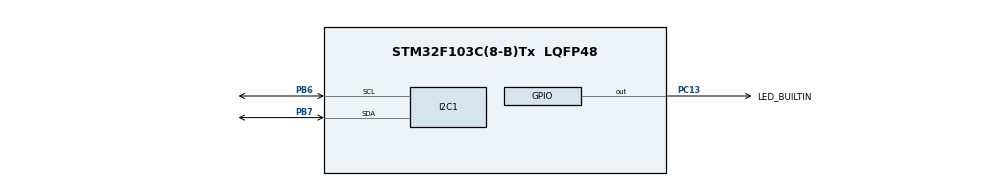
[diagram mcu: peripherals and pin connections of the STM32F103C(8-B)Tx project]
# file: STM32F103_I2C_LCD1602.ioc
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Mcu.Family=STM32F1
Mcu.Name=STM32F103C(8-B)Tx
Mcu.Package=LQFP48
NVIC.I2C1_EV_IRQn=true\:1\:0\:true\:false\:true\:true\:true\:true
NVIC.PriorityGroup=NVIC_PRIORITYGROUP_4
NVIC.RTC_IRQn=true\:0\:0\:false\:false\:true\:true\:true\:true
PA13.Mode=Serial_Wire
PA13.Signal=SYS_JTMS-SWDIO
PA14.Mode=Serial_Wire
PA14.Signal=SYS_JTCK-SWCLK
PB6.Mode=I2C
PB6.Signal=I2C1_SCL
PB7.Mode=I2C
PB7.Signal=I2C1_SDA
PC13-TAMPER-RTC.GPIO_Label=LED_BUILTIN
PC13-TAMPER-RTC.Signal=GPIO_Output
PC14-OSC32_IN.Mode=LSE-External-Oscillator
PC14-OSC32_IN.Signal=RCC_OSC32_IN
PC15-OSC32_OUT.Mode=LSE-External-Oscillator
PC15-OSC32_OUT.Signal=RCC_OSC32_OUT
ProjectManager.HeapSize=0x200
ProjectManager.StackSize=0x400
ProjectManager.TargetToolchain=Makefile
RCC.APB1Freq_Value=8000000
RCC.APB2Freq_Value=8000000
RCC.RTCClockSelection=RCC_RTCCLKSOURCE_LSE
RTC.Date=11
RTC.Format=RTC_FORMAT_BIN
RTC.Month=RTC_MONTH_NOVEMBER
RTC.Year=24
VP_RTC_VS_RTC_Activate.Mode=RTC_Enabled
VP_RTC_VS_RTC_Calendar.Mode=RTC_Calendar
board=custom

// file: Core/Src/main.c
/* USER CODE BEGIN Header */
/**
 ******************************************************************************
 * @file           : main.c
 * @brief          : Main program body
 ******************************************************************************
 * @attention
 *
 * Copyright (c) 2024 STMicroelectronics.
 * All rights reserved.
 *
 * This software is licensed under terms that can be found in the LICENSE file
 * in the root directory of this software component.
 * If no LICENSE file comes with this software, it is provided AS-IS.
 *
 ******************************************************************************
 */
/* USER CODE END Header */
#include "main.h"

/* USER CODE BEGIN Includes */
#include <stdio.h>

#include "hd44780.h"
/* USER CODE END Includes */

I2C_HandleTypeDef hi2c1;

RTC_HandleTypeDef hrtc;

/* USER CODE BEGIN PV */
Hd44780_Handle_t lcd_handle;
I2cConfig_t lcdi2c_config;

/* USER CODE END PV */

void SystemClock_Config(void);
static void MX_GPIO_Init(void);
static void MX_I2C1_Init(void);
static void MX_RTC_Init(void);
/* USER CODE BEGIN PFP */
void ToggleLED(void);

/* USER CODE END PFP */

int main(void)
{

  /* MCU Configuration--------------------------------------------------------*/

  /* Reset of all peripherals, Initializes the Flash interface and the Systick. */
  HAL_Init();

  /* Configure the system clock */
  SystemClock_Config();

  /* Initialize all configured peripherals */
  MX_GPIO_Init();
  MX_I2C1_Init();
  MX_RTC_Init();
  /* USER CODE BEGIN 2 */

    // initialize LCD
    lcdi2c_config.hi2c = &hi2c1;
    lcdi2c_config.lcd_addr = LCD_HAL_I2C_ADDRESS_DEFAULT;

    lcd_handle.i2cConfig = &lcdi2c_config;
    lcd_handle.init.cols = 16u;
    lcd_handle.init.rows = 2u;
    lcd_handle.init.num_dispLines = HD44780_FS_NDL_2_LINE;
    lcd_handle.init.char_font = HD44780_FS_FONT_5X8_DOTS;

    lcd_handle._status._ledState = 0u;
    lcd_handle._status._funcSet = 0u;
    lcd_handle._status._dispCtrl = 0u;
    lcd_handle._status._ems = 0u;
    Hd44780_Init(&lcd_handle);

  /* USER CODE END 2 */

  /* Infinite loop */
  /* USER CODE BEGIN WHILE */
    Hd44780_ToggleBlink(&lcd_handle, HD44780_OFF);
    Hd44780_ToggleCursor(&lcd_handle, HD44780_OFF);

    char timestr[11] = {0};
    char datestr[17] = {0};

    RTC_TimeTypeDef time, prevtime;
    RTC_DateTypeDef date;
    HAL_RTC_GetTime(&hrtc, &time, RTC_FORMAT_BIN);
    HAL_RTC_GetDate(&hrtc, &date, RTC_FORMAT_BIN);
    HAL_RTC_GetTime(&hrtc, &prevtime, RTC_FORMAT_BIN);
    sprintf(datestr, "%02d/%02d/20%d", date.Date, date.Month, date.Year);
    Hd44780_MoveCursor(&lcd_handle, 2, 1);
    Hd44780_Print(&lcd_handle, datestr);

    sprintf(timestr, "%02d:%02d:%02d", time.Hours, time.Minutes, time.Seconds);
    Hd44780_MoveCursor(&lcd_handle, 1, 1);
    Hd44780_Print(&lcd_handle, timestr);

    while (1)
    {
    /* USER CODE END WHILE */

    /* USER CODE BEGIN 3 */
        /* currTick = millis() */
        HAL_RTC_GetTime(&hrtc, &time, RTC_FORMAT_BIN);
        if (time.Seconds != prevtime.Seconds)
        {
            sprintf(timestr, "%02d", time.Seconds);
            Hd44780_MoveCursor(&lcd_handle, 1, 7);
            Hd44780_Print(&lcd_handle, timestr);
        }
        if(time.Minutes != prevtime.Minutes)
        {
            sprintf(timestr, "%02d", time.Minutes);
            Hd44780_MoveCursor(&lcd_handle, 1, 4);
            Hd44780_Print(&lcd_handle, timestr);
        }
        if (time.Hours != prevtime.Hours)
        {
            sprintf(timestr, "%02d", time.Hours);
            Hd44780_MoveCursor(&lcd_handle, 1, 1);
            Hd44780_Print(&lcd_handle, timestr);
        }

        /* prevTick = currTick */
        HAL_RTC_GetTime(&hrtc, &prevtime, RTC_FORMAT_BIN);
        HAL_Delay(1000);
    }
  /* USER CODE END 3 */
}

void SystemClock_Config(void)
{
  RCC_OscInitTypeDef RCC_OscInitStruct = {0};
  RCC_ClkInitTypeDef RCC_ClkInitStruct = {0};
  RCC_PeriphCLKInitTypeDef PeriphClkInit = {0};

  /** Initializes the RCC Oscillators according to the specified parameters
  * in the RCC_OscInitTypeDef structure.
  */
  RCC_OscInitStruct.OscillatorType = RCC_OSCILLATORTYPE_HSI|RCC_OSCILLATORTYPE_LSE;
  RCC_OscInitStruct.LSEState = RCC_LSE_ON;
  RCC_OscInitStruct.HSIState = RCC_HSI_ON;
  RCC_OscInitStruct.HSICalibrationValue = RCC_HSICALIBRATION_DEFAULT;
  RCC_OscInitStruct.PLL.PLLState = RCC_PLL_NONE;
  if (HAL_RCC_OscConfig(&RCC_OscInitStruct) != HAL_OK)
  {
    Error_Handler();
  }

  /** Initializes the CPU, AHB and APB buses clocks
  */
  RCC_ClkInitStruct.ClockType = RCC_CLOCKTYPE_HCLK|RCC_CLOCKTYPE_SYSCLK
                              |RCC_CLOCKTYPE_PCLK1|RCC_CLOCKTYPE_PCLK2;
  RCC_ClkInitStruct.SYSCLKSource = RCC_SYSCLKSOURCE_HSI;
  RCC_ClkInitStruct.AHBCLKDivider = RCC_SYSCLK_DIV1;
  RCC_ClkInitStruct.APB1CLKDivider = RCC_HCLK_DIV1;
  RCC_ClkInitStruct.APB2CLKDivider = RCC_HCLK_DIV1;

  if (HAL_RCC_ClockConfig(&RCC_ClkInitStruct, FLASH_LATENCY_0) != HAL_OK)
  {
    Error_Handler();
  }
  PeriphClkInit.PeriphClockSelection = RCC_PERIPHCLK_RTC;
  PeriphClkInit.RTCClockSelection = RCC_RTCCLKSOURCE_LSE;
  if (HAL_RCCEx_PeriphCLKConfig(&PeriphClkInit) != HAL_OK)
  {
    Error_Handler();
  }
}

static void MX_I2C1_Init(void)
{

  hi2c1.Instance = I2C1;
  hi2c1.Init.ClockSpeed = 100000;
  hi2c1.Init.DutyCycle = I2C_DUTYCYCLE_2;
  hi2c1.Init.OwnAddress1 = 0;
  hi2c1.Init.AddressingMode = I2C_ADDRESSINGMODE_7BIT;
  hi2c1.Init.DualAddressMode = I2C_DUALADDRESS_DISABLE;
  hi2c1.Init.OwnAddress2 = 0;
  hi2c1.Init.GeneralCallMode = I2C_GENERALCALL_DISABLE;
  hi2c1.Init.NoStretchMode = I2C_NOSTRETCH_DISABLE;
  if (HAL_I2C_Init(&hi2c1) != HAL_OK)
  {
    Error_Handler();
  }

}

static void MX_RTC_Init(void)
{

  RTC_TimeTypeDef sTime = {0};
  RTC_DateTypeDef DateToUpdate = {0};

  /** Initialize RTC Only
  */
  hrtc.Instance = RTC;
  hrtc.Init.AsynchPrediv = RTC_AUTO_1_SECOND;
  hrtc.Init.OutPut = RTC_OUTPUTSOURCE_ALARM;
  if (HAL_RTC_Init(&hrtc) != HAL_OK)
  {
    Error_Handler();
  }

  /** Initialize RTC and set the Time and Date
  */
  sTime.Hours = 0;
  sTime.Minutes = 0;
  sTime.Seconds = 0;

  if (HAL_RTC_SetTime(&hrtc, &sTime, RTC_FORMAT_BIN) != HAL_OK)
  {
    Error_Handler();
  }
  DateToUpdate.WeekDay = RTC_WEEKDAY_MONDAY;
  DateToUpdate.Month = RTC_MONTH_NOVEMBER;
  DateToUpdate.Date = 11;
  DateToUpdate.Year = 24;

  if (HAL_RTC_SetDate(&hrtc, &DateToUpdate, RTC_FORMAT_BIN) != HAL_OK)
  {
    Error_Handler();
  }

}

static void MX_GPIO_Init(void)
{
  GPIO_InitTypeDef GPIO_InitStruct = {0};

  /* GPIO Ports Clock Enable */
  __HAL_RCC_GPIOC_CLK_ENABLE();
  __HAL_RCC_GPIOA_CLK_ENABLE();
  __HAL_RCC_GPIOB_CLK_ENABLE();

  /*Configure GPIO pin Output Level */
  HAL_GPIO_WritePin(LED_BUILTIN_GPIO_Port, LED_BUILTIN_Pin, GPIO_PIN_RESET);

  /*Configure GPIO pin : LED_BUILTIN_Pin */
  GPIO_InitStruct.Pin = LED_BUILTIN_Pin;
  GPIO_InitStruct.Mode = GPIO_MODE_OUTPUT_PP;
  GPIO_InitStruct.Pull = GPIO_NOPULL;
  GPIO_InitStruct.Speed = GPIO_SPEED_FREQ_LOW;
  HAL_GPIO_Init(LED_BUILTIN_GPIO_Port, &GPIO_InitStruct);

}

/* USER CODE BEGIN 4 */
void ToggleLED(void)
{
    static uint32_t currTick = 0u;
    if (currTick++ >= 600u)
    {
        /* toggle every 100ms */
        HAL_GPIO_TogglePin(LED_BUILTIN_GPIO_Port, LED_BUILTIN_Pin);
        currTick = 0u;
    }
}

// void HAL_RTCEx_RTCEventCallback(RTC_HandleTypeDef *hrtc)
// {
//     static RTC_TimeTypeDef time, prevtime;
//     HAL_RTC_GetTime(hrtc, &time, RTC_FORMAT_BIN);
//     HAL_RTC_GetTime(hrtc, &prevtime, RTC_FORMAT_BIN);
//     char timestr[11] = {0};

//     /* currTick = millis() */
//     HAL_RTC_GetTime(hrtc, &time, RTC_FORMAT_BIN);
//     if (time.Seconds != prevtime.Seconds)
//     {
//         sprintf(timestr, "%02d", time.Seconds);
//         Hd44780_MoveCursor(&lcd_handle, 1, 7);
//         Hd44780_Print(&lcd_handle, timestr);
//     }
//     if(time.Minutes != prevtime.Minutes)
//     {
//         sprintf(timestr, "%02d", time.Minutes);
//         Hd44780_MoveCursor(&lcd_handle, 1, 4);
//         Hd44780_Print(&lcd_handle, timestr);
//     }
//     if (time.Hours != prevtime.Hours)
//     {
//         sprintf(timestr, "%02d", time.Hours);
//         Hd44780_MoveCursor(&lcd_handle, 1, 1);
//         Hd44780_Print(&lcd_handle, timestr);
//     }

//     /* prevTick = currTick */
//     HAL_RTC_GetTime(hrtc, &prevtime, RTC_FORMAT_BIN);
// }

/* USER CODE END 4 */

void Error_Handler(void)
{
    __disable_irq();
    while (1)
    {
    }
}
